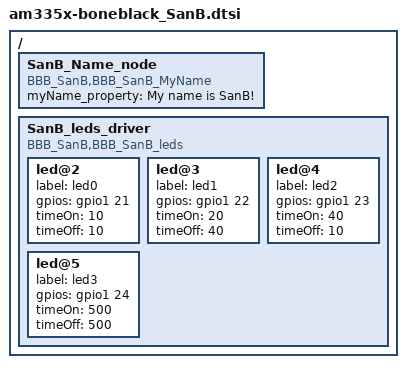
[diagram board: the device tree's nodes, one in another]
/*
 * Copyright (C) SanB
 *
 * This program is free software; you can redistribute it and/or modify
 * it under the terms of the GNU General Public License version 2 as
 * published by the Free Software Foundation.
 */

/ {
    SanB_Name_node {
        compatible = "BBB_SanB,BBB_SanB_MyName";
        myName_property = "My name is SanB!";
    };
};

/ {
	SanB_leds_driver {
		/*pinctrl-names = "default", "sleep";
		pinctrl-0 = <&user_leds_default>;
		pinctrl-1 = <&user_leds_sleep>;*/

		compatible = "BBB_SanB,BBB_SanB_leds";

		led@2 {
			label = "led0";
			gpios = <&gpio1 21 GPIO_ACTIVE_HIGH>;
			/*default-state = "keep";*/
			timeOn = <10>;
			timeOff = <10>;
		};

		led@3 {
			label = "led1";
			gpios = <&gpio1 22 GPIO_ACTIVE_HIGH>;
			/*default-state = "keep";*/
			timeOn = <20>;
			timeOff = <40>;
		};

		led@4 {
			label = "led2";
			gpios = <&gpio1 23 GPIO_ACTIVE_HIGH>;
			/*default-state = "keep";*/
			timeOn = <40>;
			timeOff = <10>;
		};

		led@5 {
			label = "led3";
			gpios = <&gpio1 24 GPIO_ACTIVE_HIGH>;
			/*default-state = "keep";*/
			timeOn = <500>;
			timeOff = <500>;
		};
	};
};
	

